# MKL24Z4 register map
Vendor: Freescale Semiconductor, Inc.; Series: Kinetis_L; File version: 1.6
CPU: CM0PLUS r0p0, little endian, no MPU, no FPU, VTOR, 2 interrupt priority bits
Registers are 32-bit, read-write, reset 0x0 unless marked. A register's access mark holds for its fields unless they carry their own. Offsets are from the block's base; [hi:lo] are bit positions; {n}, {i} and the like mark numbered series.

## SPI0 — Serial Peripheral Interface
Base 0x40076000; register names take the prefix SPI0_
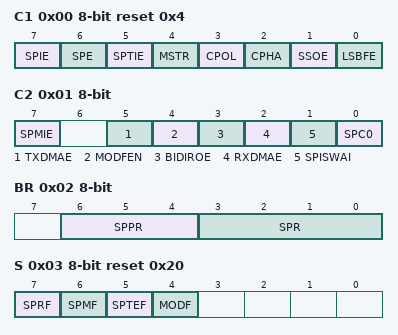
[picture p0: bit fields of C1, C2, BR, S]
0x00 C1 8-bit reset 0x4 — SPI control register 1
  [7] SPIE — SPI interrupt enable: for SPRF and MODF
    0=Interrupts from SPRF and MODF are inhibited-use polling; 1=Request a hardware interrupt when SPRF or MODF is 1
  [6] SPE — SPI system enable
    0=SPI system inactive; 1=SPI system enabled
  [5] SPTIE — SPI transmit interrupt enable
    0=Interrupts from SPTEF inhibited (use polling); 1=When SPTEF is 1, hardware interrupt requested
  [4] MSTR — Master/slave mode select
    0=SPI module configured as a slave SPI device; 1=SPI module configured as a master SPI device
  [3] CPOL — Clock polarity
    0=Active-high SPI clock (idles low); 1=Active-low SPI clock (idles high)
  [2] CPHA — Clock phase
    0=First edge on SPSCK occurs at the middle of the first cycle of a data transfer; 1=First edge on SPSCK occurs at the start of the first cycle of a data transfer
  [1] SSOE — Slave select output enable
    0=When MODFEN is 0: In master mode, SS pin function is general-purpose I/O (not SPI). In slave mode, SS pin function is slave select input. When MODFEN is 1: In master mode, SS pin function is SS input for mode fault. In slave mode, SS pin function is slave select input.; 1=When MODFEN is 0: In master mode, SS pin function is general-purpose I/O (not SPI). In slave mode, SS pin function is slave select input. When MODFEN is 1: In master mode, SS pin function is automatic SS output. In slave mode: SS pin function is slave select input.
  [0] LSBFE — LSB first (shifter direction)
    0=SPI serial data transfers start with most significant bit; 1=SPI serial data transfers start with least significant bit
0x01 C2 8-bit — SPI control register 2
  [7] SPMIE — SPI match interrupt enable
    0=Interrupts from SPMF inhibited (use polling); 1=When SPMF is 1, requests a hardware interrupt
  [5] TXDMAE — Transmit DMA enable
    0=DMA request for transmit is disabled and interrupt from SPTEF is allowed; 1=DMA request for transmit is enabled and interrupt from SPTEF is disabled
  [4] MODFEN — Master mode-fault function enable
    0=Mode fault function disabled, master SS pin reverts to general-purpose I/O not controlled by SPI; 1=Mode fault function enabled, master SS pin acts as the mode fault input or the slave select output
  [3] BIDIROE — Bidirectional mode output enable
    0=Output driver disabled so SPI data I/O pin acts as an input; 1=SPI I/O pin enabled as an output
  [2] RXDMAE — Receive DMA enable
    0=DMA request for receive is disabled and interrupt from SPRF is allowed; 1=DMA request for receive is enabled and interrupt from SPRF is disabled
  [1] SPISWAI — SPI stop in wait mode
    0=SPI clocks continue to operate in wait mode; 1=SPI clocks stop when the MCU enters wait mode
  [0] SPC0 — SPI pin control 0
    0=SPI uses separate pins for data input and data output (pin mode is normal). In master mode of operation: MISO is master in and MOSI is master out. In slave mode of operation: MISO is slave out and MOSI is slave in.; 1=SPI configured for single-wire bidirectional operation (pin mode is bidirectional). In master mode of operation: MISO is not used by SPI; MOSI is master in when BIDIROE is 0 or master I/O when BIDIROE is 1. In slave mode of operation: MISO is slave in when BIDIROE is 0 or slave I/O when BIDIROE is 1; MOSI is not used by SPI.
0x02 BR 8-bit — SPI baud rate register
  [6:4] SPPR — SPI baud rate prescale divisor
    {v}=Baud rate prescaler divisor is {v+1} (v=0..7)
  [3:0] SPR — SPI baud rate divisor
    0=Baud rate divisor is 2; 1=Baud rate divisor is 4; 2=Baud rate divisor is 8; 3=Baud rate divisor is 16; 4=Baud rate divisor is 32; 5=Baud rate divisor is 64; 6=Baud rate divisor is 128; 7=Baud rate divisor is 256; 8=Baud rate divisor is 512
0x03 S 8-bit ro reset 0x20 — SPI status register
  [7] SPRF — SPI read buffer full flag
    0=No data available in the receive data buffer; 1=Data available in the receive data buffer
  [6] SPMF — SPI match flag
    0=Value in the receive data buffer does not match the value in the M register; 1=Value in the receive data buffer matches the value in the M register
  [5] SPTEF — SPI transmit buffer empty flag
    0=SPI transmit buffer not empty; 1=SPI transmit buffer empty
  [4] MODF — Master mode fault flag
    0=No mode fault error; 1=Mode fault error detected
0x05 D 8-bit — SPI data register
  [7:0] Bits — Data (low byte)
0x07 M 8-bit — SPI match register
  [7:0] Bits — Hardware compare value (low byte)

## SPI1 — Serial Peripheral Interface
Base 0x40077000; register names take the prefix SPI1_
Registers as SPI0.
